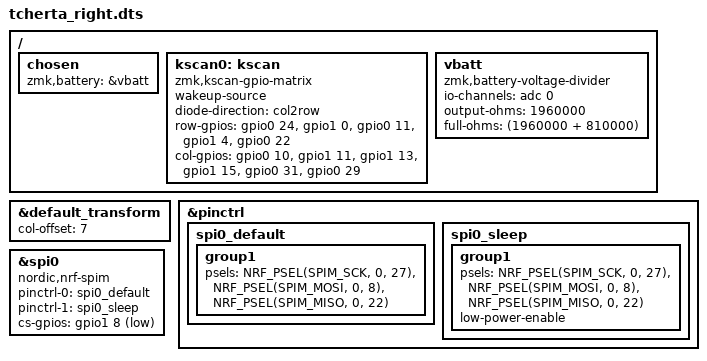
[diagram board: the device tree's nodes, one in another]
/*
*
* Copyright (c) 2021 Darryl deHaan
* SPDX-License-Identifier: MIT
*
*/

#include "tcherta.dtsi"
#include <dt-bindings/zmk/matrix_transform.h>

/{
    chosen {
        zmk,battery = &vbatt;
    };

    kscan0: kscan {
        compatible = "zmk,kscan-gpio-matrix";
        wakeup-source;

        diode-direction = "col2row";
        row-gpios
            = <&gpio0 24 (GPIO_ACTIVE_HIGH | GPIO_PULL_DOWN)>
            , <&gpio1 0 (GPIO_ACTIVE_HIGH | GPIO_PULL_DOWN)>
            , <&gpio0 11 (GPIO_ACTIVE_HIGH | GPIO_PULL_DOWN)>
            , <&gpio1 4 (GPIO_ACTIVE_HIGH | GPIO_PULL_DOWN)>

            // Seems like controller pin 1 6 is not functioning. Hence, other random one is used...
            //, <&gpio1 6 (GPIO_ACTIVE_HIGH | GPIO_PULL_DOWN)>
            , <&gpio0 22 (GPIO_ACTIVE_HIGH | GPIO_PULL_DOWN)>
            ;

            // use it as nice nano
        col-gpios
            = <&gpio0 10 GPIO_ACTIVE_HIGH>
            , <&gpio1 11 GPIO_ACTIVE_HIGH>
            , <&gpio1 13 GPIO_ACTIVE_HIGH>
            , <&gpio1 15 GPIO_ACTIVE_HIGH>
            , <&gpio0 31 GPIO_ACTIVE_HIGH>      // Better to use 0 2, but that pin seem to not work
            , <&gpio0 29 GPIO_ACTIVE_HIGH>
            ;

            // use it as promicro
            /*
        col-gpios
            = <&pro_micro 16 GPIO_ACTIVE_HIGH>
            , <&pro_micro 14 GPIO_ACTIVE_HIGH>
            , <&pro_micro 15 GPIO_ACTIVE_HIGH>
            , <&pro_micro 18 GPIO_ACTIVE_HIGH>
            , <&pro_micro 19 GPIO_ACTIVE_HIGH>
            , <&pro_micro 20 GPIO_ACTIVE_HIGH>
            ;
            */
    };

    vbatt: vbatt {
        compatible = "zmk,battery-voltage-divider";
        io-channels = <&adc 0>;
        output-ohms = <1960000>;
        full-ohms = <(1960000 + 810000)>;
    };

};

&default_transform {
    col-offset = <7>;
};

&pinctrl {
    spi0_default: spi0_default {
        group1 {
            psels = <NRF_PSEL(SPIM_SCK, 0, 27)>,
                <NRF_PSEL(SPIM_MOSI, 0, 8)>,
                <NRF_PSEL(SPIM_MISO, 0, 22)>;
        };
    };

    spi0_sleep: spi0_sleep {
        group1 {
            psels = <NRF_PSEL(SPIM_SCK, 0, 27)>,
                <NRF_PSEL(SPIM_MOSI, 0, 8)>,
                <NRF_PSEL(SPIM_MISO, 0, 22)>;
            low-power-enable;
        };
    };
};

&spi0 {
    status = "okay";
    compatible = "nordic,nrf-spim";
    pinctrl-0 = <&spi0_default>;
    pinctrl-1 = <&spi0_sleep>;
    pinctrl-names = "default", "sleep";
    cs-gpios = <&gpio1 8 GPIO_ACTIVE_LOW>;
};
